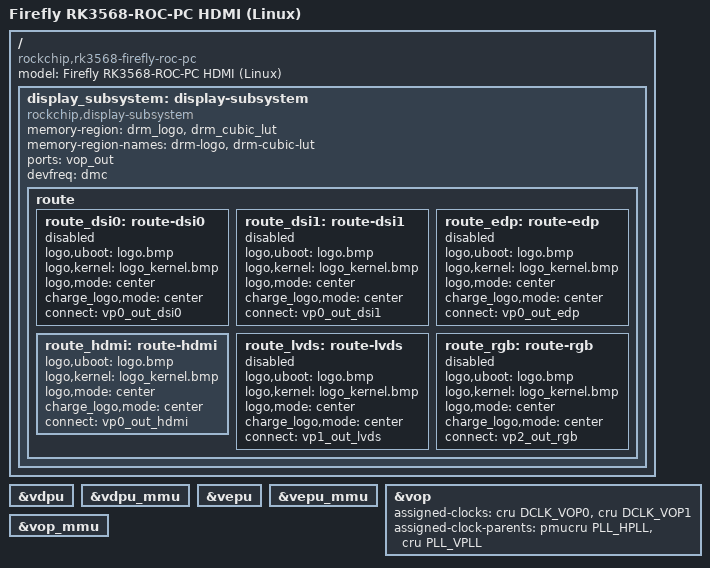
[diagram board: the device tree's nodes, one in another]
// SPDX-License-Identifier: (GPL-2.0+ OR MIT)
/*
 * Copyright (c) 2020 Rockchip Electronics Co., Ltd.
 *
 */

/dts-v1/;

#include "rk3568-firefly-roc-pc.dtsi"

/*
*								select camera
*
* using single camera xc7160        --->  rk3568-firefly-roc-pc-cam-8ms1m.dtsi
* using dual camera gc2053/gc2093   --->  rk3568-firefly-roc-pc-cam-2ms2m.dtsi
*
*/
#include "rk3568-firefly-roc-pc-cam-8ms1m.dtsi"

/ {
    model = "Firefly RK3568-ROC-PC HDMI (Linux)";
    compatible = "rockchip,rk3568-firefly-roc-pc", "rockchip,rk3568";

	display_subsystem: display-subsystem {
		compatible = "rockchip,display-subsystem";
		memory-region = <&drm_logo>, <&drm_cubic_lut>;
		memory-region-names = "drm-logo", "drm-cubic-lut";
		ports = <&vop_out>;
		devfreq = <&dmc>;

		route {
			route_dsi0: route-dsi0 {
				status = "disabled";
				logo,uboot = "logo.bmp";
				logo,kernel = "logo_kernel.bmp";
				logo,mode = "center";
				charge_logo,mode = "center";
				connect = <&vp0_out_dsi0>;
			};
			route_dsi1: route-dsi1 {
				status = "disabled";
				logo,uboot = "logo.bmp";
				logo,kernel = "logo_kernel.bmp";
				logo,mode = "center";
				charge_logo,mode = "center";
				connect = <&vp0_out_dsi1>;
			};
			route_edp: route-edp {
				status = "disabled";
				logo,uboot = "logo.bmp";
				logo,kernel = "logo_kernel.bmp";
				logo,mode = "center";
				charge_logo,mode = "center";
				connect = <&vp0_out_edp>;
			};
			route_hdmi: route-hdmi {
				status = "disabled";
				logo,uboot = "logo.bmp";
				logo,kernel = "logo_kernel.bmp";
				logo,mode = "center";
				charge_logo,mode = "center";
				connect = <&vp1_out_hdmi>;
			};
			route_lvds: route-lvds {
				status = "disabled";
				logo,uboot = "logo.bmp";
				logo,kernel = "logo_kernel.bmp";
				logo,mode = "center";
				charge_logo,mode = "center";
				connect = <&vp1_out_lvds>;
			};
			route_rgb: route-rgb {
				status = "disabled";
				logo,uboot = "logo.bmp";
				logo,kernel = "logo_kernel.bmp";
				logo,mode = "center";
				charge_logo,mode = "center";
				connect = <&vp2_out_rgb>;
			};
		};
	};
};

//&video_phy0 {
//	status = "okay";
//};

//&display_subsystem {
//    status = "okay";
//};

//&gpu {
//	mali-supply = <&vdd_gpu>;
//	status = "okay";
//};

//&hdmi {
//	status = "okay";
//};

//&hdmi_in_vp0 {
//	status = "okay";
//};

//&hdmi_in_vp1 {
//	status = "disabled";
//};

//&hdmi_sound {
//	status = "okay";
//};

&route_hdmi {
    status = "okay";
    connect = <&vp0_out_hdmi>;
};

&vdpu {
	status = "okay";
};

&vdpu_mmu {
	status = "okay";
};

&vepu {
	status = "okay";
};

&vepu_mmu {
	status = "okay";
};

&vop {
	status = "okay";
	assigned-clocks = <&cru DCLK_VOP0>, <&cru DCLK_VOP1>;
	assigned-clock-parents = <&pmucru PLL_HPLL>, <&cru PLL_VPLL>;
};

&vop_mmu {
	status = "okay";
};
